# SN32F400 register map
Vendor: SONiX Technology Co., Ltd.; Series: SN32F400; File version: 1.1
CPU: CM0 r0p0, little endian, no MPU, no FPU, 2 interrupt priority bits
Registers are 32-bit, read-write, reset 0x0 unless marked. A register's access mark holds for its fields unless they carry their own. Offsets are from the block's base; [hi:lo] are bit positions; {n}, {i} and the like mark numbered series.

## SN_CMP — Comparator
Base 0x40028000
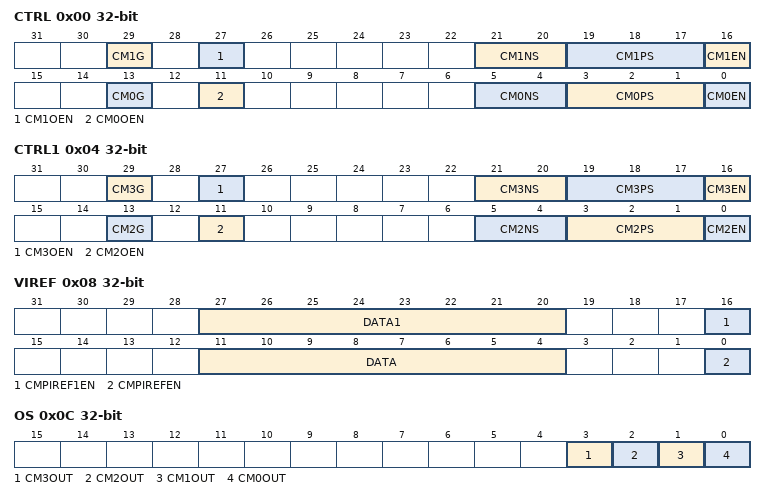
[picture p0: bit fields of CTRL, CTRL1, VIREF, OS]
0x00 CTRL — Offset:0x00 CMP Control register
  [29] CM1G — CMP1 interrupt trigger direction control bit
    0=Falling range trigger (CMP1 output status is from high to low as V+ is less than V-); 1=Rising edge trigger (CMP1 output status is from low to high as V+ is more than V-)
  [27] CM1OEN — CMP1 Output pin control bits
    0=Disable CM1O; 1=Enable CM1O
  [21:20] CM1NS — CMP1 Negative input pin
    0=CM1N0 (CM1N0 is negative input pin); 1=CM1N1 (CM1N1 is negative input pin); 2=CM1N2 (CM1N2 is negative input pin); 3=VIREF1 (CM1N0/CM1N1/CM1N2 pins are GPIO mode)
  [19:17] CM1PS — CMP1 Positive input selection bits
    0=VIREF1 (CM1P0/CM1P1/CM1P2 pins are GPIO mode); 1=CM1P0 (CM1P0 is positive input pin); 2=CM1P1 (CM1P1 is positive input pin); 3=CM1P2 (CM1P2 is positive input pin); 4=OP0O (OP0O is positive input pin); 5=OP1O (OP1O is positive input pin); 6=OP2O (OP2O is positive input pin)
  [16] CM1EN — CMP1 Enable bit
    0=Disable CMP1; 1=Enable CMP1
  [13] CM0G — CMP0 interrupt trigger direction control bit
    0=Falling range trigger (CMP0 output status is from high to low as V+ is less than V-); 1=Rising edge trigger (CMP0 output status is from low to high as V+ is more than V-)
  [11] CM0OEN — CMP0 Output pin control bits
    0=Disable CM0O; 1=Enable CM0O
  [5:4] CM0NS — CMP0 Negative input pin
    0=CM0N0 (CM0N0 is negative input pin); 1=CM0N1 (CM0N1 is negative input pin); 2=CM0N2 (CM0N2 is negative input pin); 3=VIREF0 (CM0N0/CM0N1/CM0N2 pins are GPIO mode)
  [3:1] CM0PS — CMP0 Positive input selection bits
    0=VIREF0 (CM0P0/CM0P1/CM0P2 pins are GPIO mode); 1=CM0P0 (CM0P0 is positive input pin); 2=CM0P1 (CM0P1 is positive input pin); 3=CM0P2 (CM0P2 is positive input pin); 4=OP0O (OP0O is positive input pin); 5=OP1O (OP1O is positive input pin); 6=OP2O (OP2O is positive input pin)
  [0] CM0EN — CMP0 Enable bit
    0=Disable CMP0; 1=Enable CMP0
0x04 CTRL1 — Offset:0x04 CMP Control register 1
  [29] CM3G — CMP3 interrupt trigger direction control bit
    0=Falling range trigger (CMP3 output status is from high to low as V+ is less than V-); 1=Rising edge trigger (CMP3 output status is from low to high as V+ is more than V-)
  [27] CM3OEN — CMP3 Output pin control bits
    0=Disable CM3O; 1=Enable CM3O
  [21:20] CM3NS — CMP3 Negative input pin
    0=CM3N0 (CM3N0 is negative input pin); 1=CM3N1 (CM3N1 is negative input pin); 2=CM3N2 (CM3N2 is negative input pin); 3=VIREF3 (CM3N0/CM3N1/CM3N2 pins are GPIO mode)
  [19:17] CM3PS — CMP3 Positive input selection bits
    0=VIREF3 (CM3P0/CM3P1/CM3P2 pins are GPIO mode); 1=CM3P0 (CM3P0 is positive input pin); 2=CM3P1 (CM3P1 is positive input pin); 3=CM3P2 (CM3P2 is positive input pin)
  [16] CM3EN — CMP3 Enable bit
    0=Disable CMP3; 1=Enable CMP3
  [13] CM2G — CMP2 interrupt trigger direction control bit
    0=Falling range trigger (CMP2 output status is from high to low as V+ is less than V-); 1=Rising edge trigger (CMP2 output status is from low to high as V+ is more than V-)
  [11] CM2OEN — CMP2 Output pin control bits
    0=Disable CM2O; 1=Enable CM2O
  [5:4] CM2NS — CMP2 Negative input pin
    0=CM2N0 (CM2N0 is negative input pin); 1=CM2N1 (CM2N1 is negative input pin); 2=CM2N2 (CM2N2 is negative input pin); 3=VIREF2 (CM2N0/CM2N1/CM2N2 pins are GPIO mode)
  [3:1] CM2PS — CMP2 Positive input selection bits
    0=VIREF2 (CM2P0/CM2P1/CM2P2 pins are GPIO mode); 1=CM2P0 (CM2P0 is positive input pin); 2=CM2P1 (CM2P1 is positive input pin); 3=CM2P2 (CM2P2 is positive input pin); 4=OP0O (OP0O is positive input pin); 5=OP1O (OP1O is positive input pin); 6=OP2O (OP2O is positive input pin)
  [0] CM2EN — CMP2 Enable bit
    0=Disable CMP2; 1=Enable CMP2
0x08 VIREF — Offset:0x08 CMP Internal Reference Voltage register
  [27:20] DATA1 — 8-bit DAC1 setup data bits
  [16] CMPIREF1EN — CMP3 internal reference voltage (VIREF3) enable
    0=Disable CMP3 internal reference voltage; 1=Enable CMP3 internal reference voltage
  [11:4] DATA — 8-bit DAC0 setup data bits
  [0] CMPIREFEN — CMP0/1/2 internal reference voltage (VIREF0/1/2) enable
    0=Disable CMP0/1/2 internal reference voltage; 1=Enable CMP0/1/2 internal reference voltage
0x0C OS ro — Offset:0xC CMP Output Status register
  [3] CM3OUT — CMP3 Output flag bit
    0=CMP3 V+ is less than V- (V3+ is less than V3- voltage); 1=CMP3 V+ is more than V- (V3+ is more than V3- voltage)
  [2] CM2OUT — CMP2 Output flag bit
    0=CMP2 V+ is less than V- (V2+ is less than V2- voltage); 1=CMP2 V+ is more than V- (V2+ is more than V2- voltage)
  [1] CM1OUT — CMP1 Output flag bit
    0=CMP1 V+ is less than V- (V1+ is less than V1-); 1=CMP1 V+ is more than V- (V1+ is more than V1- voltage)
  [0] CM0OUT — CMP0 Output flag bit
    0=CMP0 V+ is less than V- (V0+ is less than V0-); 1=CMP0 V+ is more than V- (V0+ is more than V0-)
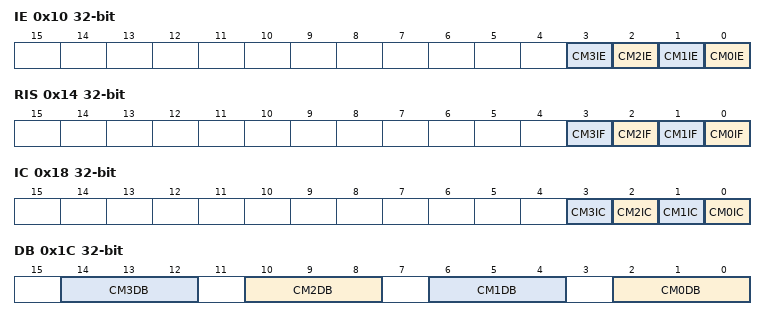
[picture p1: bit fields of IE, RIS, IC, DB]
0x10 IE — Offset:0x10 CMP Interrupt Enable register
  [n] CM{n}IE (n=0..3) — CMP{n} interrupt enable
    0=Disable CMP{n} interrupt; 1=Enable CMP{n} interrupt
0x14 RIS ro — Offset:0x14 CMP Raw Interrupt Status register
  [n] CM{n}IF (n=0..3) — CMP{n} raw interrupt flag
    0=None (No interrupt on CMP{n}); 1=Met interrupt requirements (Interrupt requirements met on CMP{n})
0x18 IC wo — Offset:0x18 CMP Interrupt Clear register
  [n] CM{n}IC (n=0..3) — CMP{n} interrupt flag clear bit
    0=None (No effect); 1=Clear CMP{n} interrupt flag
0x1C DB — Offset:0x1C CMP Interrupt Clear register
  [4n+2:4n] CM{n}DB (n=0..3) — Count for CMP{n} output debounce time
    0=000b (No CMP{n} output debounce time); 1=001b (CMP{n} output debounce time=2*CMP{n}_PCLK); 2=010b (CMP{n} output debounce time=4*CMP{n}_PCLK); 3=011b (CMP{n} output debounce time=8*CMP{n}_PCLK); 4=100b (CMP{n} output debounce time=16*CMP{n}_PCLK); 5=101b (CMP{n} output debounce time=32*CMP{n}_PCLK); 6=110b (CMP{n} output debounce time=64*CMP{n}_PCLK); 7=111b (CMP{n} output debounce time=128*CMP{n}_PCLK)
